AUTOSAR XML (schema 4-3-0)
package /ComponentTypes
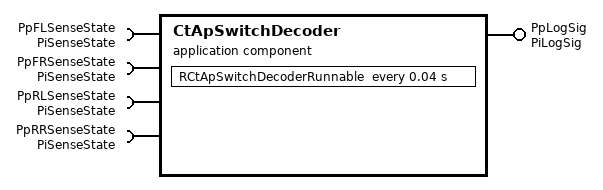
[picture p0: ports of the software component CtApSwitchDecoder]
  application sw component type CtApSwitchDecoder
    4 x require port, all with required-interface=PiSenseState:
      PpFLSenseState: nonqueued-receiver-com-spec{data-element=DePiSenseState, filter=data-filter-type=ALWAYS, init-value=0}
      PpFRSenseState: nonqueued-receiver-com-spec{data-element=DePiSenseState, filter=data-filter-type=ALWAYS}
      PpRLSenseState: nonqueued-receiver-com-spec{data-element=DePiSenseState, filter=data-filter-type=ALWAYS}
      PpRRSenseState: nonqueued-receiver-com-spec{data-element=DePiSenseState, filter=data-filter-type=ALWAYS}
    provide port PpLogSig: nonqueued-sender-com-spec{data-element=DePiLedState, init-value=0}, provided-interface=PiLogSig
    behavior CtApSwitchDecoder_InternalBehavior: supports-multiple-instantiation=true
      timing event TMT_RCtApSwitchDecoderRunnable: start-on-event=RCtApSwitchDecoderRunnable, period=0.04
      runnable RCtApSwitchDecoderRunnable
        data-receive-point-by-arguments:
          4 x access:
            REC_PpRLSenseState_DePiSenseState: accessed-variable=PpRLSenseState.DePiSenseState
            REC_PpRRSenseState_DePiSenseState: accessed-variable=PpRRSenseState.DePiSenseState
            REC_PpFLSenseState_DePiSenseState: accessed-variable=PpFLSenseState.DePiSenseState
            REC_PpFRSenseState_DePiSenseState: accessed-variable=PpFRSenseState.DePiSenseState
        data-send-points:
          access SEND_PpLogSig_DePiLedState: accessed-variable=PpLogSig.DePiLedState
  swc implementation CtApSwitchDecoder_Implementation: behavior=CtApSwitchDecoder_InternalBehavior
